AUTOSAR XML (schema 4-2-2)
package /STELLANTIS/EPT/ASWCs
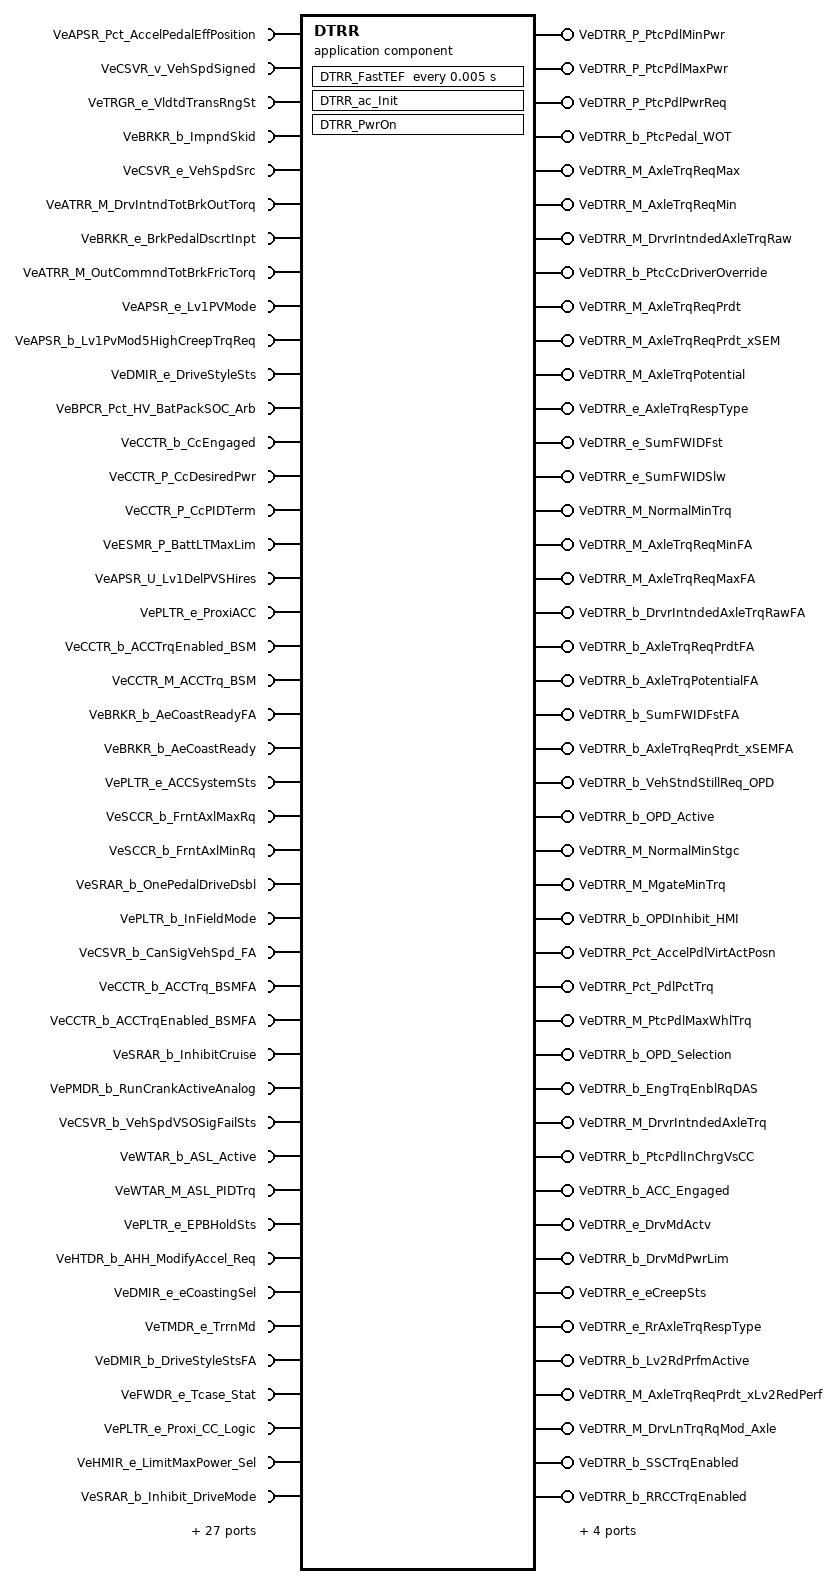
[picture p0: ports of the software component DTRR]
  application sw component type DTRR
    71 x require port:
      VeAPSR_Pct_AccelPedalEffPosition: nonqueued-receiver-com-spec{data-element=Value, init-value=0}, required-interface=VeAPSR_Pct_AccelPedalEffPosition
      VeCSVR_v_VehSpdSigned: nonqueued-receiver-com-spec{data-element=Value, init-value=0}, required-interface=VeCSVR_v_VehSpdSigned
      VeTRGR_e_VldtdTransRngSt: nonqueued-receiver-com-spec{data-element=Value, init-value=CeTRGR_e_NoSelectionAvailable}, required-interface=VeTRGR_e_VldtdTransRngSt
      VeBRKR_b_ImpndSkid: nonqueued-receiver-com-spec{data-element=Value, init-value=0}, required-interface=VeBRKR_b_ImpndSkid
      VeCSVR_e_VehSpdSrc: nonqueued-receiver-com-spec{data-element=Value, init-value=CeCSVR_e_VehSpdFrmCAN}, required-interface=VeCSVR_e_VehSpdSrc
      VeATRR_M_DrvIntndTotBrkOutTorq: nonqueued-receiver-com-spec{data-element=Value, init-value=0}, required-interface=VeATRR_M_DrvIntndTotBrkOutTorq
      VeBRKR_e_BrkPedalDscrtInpt: nonqueued-receiver-com-spec{data-element=Value, init-value=CeBRKR_e_BrkNotApplied}, required-interface=VeBRKR_e_BrkPedalDscrtInpt
      VeATRR_M_OutCommndTotBrkFricTorq: nonqueued-receiver-com-spec{data-element=Value, init-value=0}, required-interface=VeATRR_M_OutCommndTotBrkFricTorq
      VeAPSR_e_Lv1PVMode: nonqueued-receiver-com-spec{data-element=Value, init-value=CeAPSR_e_LV1PVMode_NotValid}, required-interface=VeAPSR_e_Lv1PVMode
      VeAPSR_b_Lv1PvMod5HighCreepTrqReq: nonqueued-receiver-com-spec{data-element=Value, init-value=0}, required-interface=VeAPSR_b_Lv1PvMod5HighCreepTrqReq
      VeDMIR_e_DriveStyleSts: nonqueued-receiver-com-spec{data-element=Value, init-value=CeDMIR_e_Normal}, required-interface=VeDMIR_e_DriveStyleSts
      VeBPCR_Pct_HV_BatPackSOC_Arb: nonqueued-receiver-com-spec{data-element=Value, init-value=0}, required-interface=VeBPCR_Pct_HV_BatPackSOC_Arb
      VeCCTR_b_CcEngaged: nonqueued-receiver-com-spec{data-element=Value, init-value=0}, required-interface=VeCCTR_b_CcEngaged
      VeCCTR_P_CcDesiredPwr: nonqueued-receiver-com-spec{data-element=Value, init-value=0}, required-interface=VeCCTR_P_CcDesiredPwr
      VeCCTR_P_CcPIDTerm: nonqueued-receiver-com-spec{data-element=Value, init-value=0}, required-interface=VeCCTR_P_CcPIDTerm
      VeESMR_P_BattLTMaxLim: nonqueued-receiver-com-spec{data-element=Value, init-value=0}, required-interface=VeESMR_P_BattLTMaxLim
      VeAPSR_U_Lv1DelPVSHires: nonqueued-receiver-com-spec{data-element=Value, init-value=0}, required-interface=VeAPSR_U_Lv1DelPVSHires
      VePLTR_e_ProxiACC: nonqueued-receiver-com-spec{data-element=Value, init-value=CePLTR_e_ACC_Absent}, required-interface=VePLTR_e_ProxiACC
      VeCCTR_b_ACCTrqEnabled_BSM: nonqueued-receiver-com-spec{data-element=Value, init-value=0}, required-interface=VeCCTR_b_ACCTrqEnabled_BSM
      VeCCTR_M_ACCTrq_BSM: nonqueued-receiver-com-spec{data-element=Value, init-value=0}, required-interface=VeCCTR_M_ACCTrq_BSM
      VeBRKR_b_AeCoastReadyFA: nonqueued-receiver-com-spec{data-element=Value, init-value=0}, required-interface=VeBRKR_b_AeCoastReadyFA
      VeBRKR_b_AeCoastReady: nonqueued-receiver-com-spec{data-element=Value, init-value=0}, required-interface=VeBRKR_b_AeCoastReady
      VePLTR_e_ACCSystemSts: nonqueued-receiver-com-spec{data-element=Value, init-value=CePLTR_e_Off}, required-interface=VePLTR_e_ACCSystemSts
      VeSCCR_b_FrntAxlMaxRq: nonqueued-receiver-com-spec{data-element=Value, init-value=0}, required-interface=VeSCCR_b_FrntAxlMaxRq
      VeSCCR_b_FrntAxlMinRq: nonqueued-receiver-com-spec{data-element=Value, init-value=0}, required-interface=VeSCCR_b_FrntAxlMinRq
      VeSRAR_b_OnePedalDriveDsbl: nonqueued-receiver-com-spec{data-element=Value, init-value=0}, required-interface=VeSRAR_b_OnePedalDriveDsbl
      VePLTR_b_InFieldMode: nonqueued-receiver-com-spec{data-element=Value, init-value=0}, required-interface=VePLTR_b_InFieldMode
      VeCSVR_b_CanSigVehSpd_FA: nonqueued-receiver-com-spec{data-element=Value, init-value=0}, required-interface=VeCSVR_b_CanSigVehSpd_FA
      VeCCTR_b_ACCTrq_BSMFA: nonqueued-receiver-com-spec{data-element=Value, init-value=0}, required-interface=VeCCTR_b_ACCTrq_BSMFA
      VeCCTR_b_ACCTrqEnabled_BSMFA: nonqueued-receiver-com-spec{data-element=Value, init-value=0}, required-interface=VeCCTR_b_ACCTrqEnabled_BSMFA
      VeSRAR_b_InhibitCruise: nonqueued-receiver-com-spec{data-element=Value, init-value=0}, required-interface=VeSRAR_b_InhibitCruise
      VePMDR_b_RunCrankActiveAnalog: nonqueued-receiver-com-spec{data-element=Value, init-value=0}, required-interface=VePMDR_b_RunCrankActiveAnalog
      VeCSVR_b_VehSpdVSOSigFailSts: nonqueued-receiver-com-spec{data-element=Value, init-value=0}, required-interface=VeCSVR_b_VehSpdVSOSigFailSts
      VeWTAR_b_ASL_Active: nonqueued-receiver-com-spec{data-element=Value, init-value=0}, required-interface=VeWTAR_b_ASL_Active
      VeWTAR_M_ASL_PIDTrq: nonqueued-receiver-com-spec{data-element=Value, init-value=0}, required-interface=VeWTAR_M_ASL_PIDTrq
      VePLTR_e_EPBHoldSts: nonqueued-receiver-com-spec{data-element=Value, init-value=CePLTR_e_EPBHoldSts_REL}, required-interface=VePLTR_e_EPBHoldSts
      VeHTDR_b_AHH_ModifyAccel_Req: nonqueued-receiver-com-spec{data-element=Value, init-value=0}, required-interface=VeHTDR_b_AHH_ModifyAccel_Req
      VeDMIR_e_eCoastingSel: variation-point={short-label=vpVeDMIR_e_eCoastingSel, sw-syscond=1}, nonqueued-receiver-com-spec{data-element=Value, init-value=CeDMIR_e_Level1}, required-interface=VeDMIR_e_eCoastingSel
      VeTMDR_e_TrrnMd: nonqueued-receiver-com-spec{data-element=Value, init-value=CeTMDR_e_NotDefine}, required-interface=VeTMDR_e_TrrnMd
      VeDMIR_b_DriveStyleStsFA: nonqueued-receiver-com-spec{data-element=Value, init-value=0}, required-interface=VeDMIR_b_DriveStyleStsFA
      VeFWDR_e_Tcase_Stat: nonqueued-receiver-com-spec{data-element=Value, init-value=CeFWDR_e_ShiftINProg}, required-interface=VeFWDR_e_Tcase_Stat
      VePLTR_e_Proxi_CC_Logic: nonqueued-receiver-com-spec{data-element=Value, init-value=CePLTR_e_Logic1}, required-interface=VePLTR_e_Proxi_CC_Logic
      VeHMIR_e_LimitMaxPower_Sel: nonqueued-receiver-com-spec{data-element=Value, init-value=CeHMIR_e_Not_Active}, required-interface=VeHMIR_e_LimitMaxPower_Sel
      VeSRAR_b_Inhibit_DriveMode: nonqueued-receiver-com-spec{data-element=Value, init-value=0}, required-interface=VeSRAR_b_Inhibit_DriveMode
      VeDMDR_e_TurtleMdSts: nonqueued-receiver-com-spec{data-element=Value, init-value=CeDMDR_e_No_Turtle_Mode}, required-interface=VeDMDR_e_TurtleMdSts
      VeBRKR_P_BrkPrss: nonqueued-receiver-com-spec{data-element=Value, init-value=0}, required-interface=VeBRKR_P_BrkPrss
      VePLTR_Pct_EstSlopeAnglePct: nonqueued-receiver-com-spec{data-element=Value, init-value=0}, required-interface=VePLTR_Pct_EstSlopeAnglePct
      VeAPSR_b_Lv1Pv1LimFailed: nonqueued-receiver-com-spec{data-element=Value, init-value=0}, required-interface=VeAPSR_b_Lv1Pv1LimFailed
      VeAPSR_b_Lv1Pv2LimFailed: nonqueued-receiver-com-spec{data-element=Value, init-value=0}, required-interface=VeAPSR_b_Lv1Pv2LimFailed
      VeSCCR_b_RrAxlMaxRq: nonqueued-receiver-com-spec{data-element=Value, init-value=0}, required-interface=VeSCCR_b_RrAxlMaxRq
      VeSCCR_b_RrAxlMinRq: nonqueued-receiver-com-spec{data-element=Value, init-value=0}, required-interface=VeSCCR_b_RrAxlMinRq
      VeCTCR_b_MinCreepWheelTrq_Enable: nonqueued-receiver-com-spec{data-element=Value, init-value=0}, required-interface=VeCTCR_b_MinCreepWheelTrq_Enable
      VeCTCR_M_WheelMin4ECM: nonqueued-receiver-com-spec{data-element=Value, init-value=0}, required-interface=VeCTCR_M_WheelMin4ECM
      VePLTR_b_CC_Type: nonqueued-receiver-com-spec{data-element=Value, init-value=0}, required-interface=VePLTR_b_CC_Type
      VeSTMR_e_RdPrfmMd_MinMax: nonqueued-receiver-com-spec{data-element=Value, init-value=CeSTMR_e_NoRdPerfmMdRq}, required-interface=VeSTMR_e_RdPrfmMd_MinMax
      VeSTMR_M_Lv2ReducedPrfmTrq: nonqueued-receiver-com-spec{data-element=Value, init-value=0}, required-interface=VeSTMR_M_Lv2ReducedPrfmTrq
      VeSTMR_b_Lv2ReducedPerfMode: nonqueued-receiver-com-spec{data-element=Value, init-value=0}, required-interface=VeSTMR_b_Lv2ReducedPerfMode
      VeBTQR_r_TrqDmnConvSumToAxl: nonqueued-receiver-com-spec{data-element=Value, init-value=0}, required-interface=VeBTQR_r_TrqDmnConvSumToAxl
      VeTINR_M_DrvLnTrqRq_Axle: nonqueued-receiver-com-spec{data-element=Value, init-value=0}, required-interface=VeTINR_M_DrvLnTrqRq_Axle
      VeDMIR_e_RegenSts: nonqueued-receiver-com-spec{data-element=Value, init-value=CeDMIR_e_NormalRegen}, required-interface=VeDMIR_e_RegenSts
      VeDMDR_e_DrvMdArb: nonqueued-receiver-com-spec{data-element=Value, init-value=CeDMDR_e_NoDrvMd}, required-interface=VeDMDR_e_DrvMdArb
      VeINVR_e_MtrA_InvrtrSt: nonqueued-receiver-com-spec{data-element=Value, init-value=CeINVR_e_NormalPowerStageOff}, required-interface=VeINVR_e_MtrA_InvrtrSt
      VeINVR_e_MtrB_InvrtrSt: nonqueued-receiver-com-spec{data-element=Value, init-value=CeINVR_e_NormalPowerStageOff}, required-interface=VeINVR_e_MtrB_InvrtrSt
      VePLTR_e_BSM_AxleTrq_Enbld: nonqueued-receiver-com-spec{data-element=Value, init-value=CePLTR_e_No_Req}, required-interface=VePLTR_e_BSM_AxleTrq_Enbld
      VeTMDR_e_PropulsionMd: nonqueued-receiver-com-spec{data-element=Value, init-value=CeTMDR_e_NotDefine}, required-interface=VeTMDR_e_PropulsionMd
      VeDMIR_e_CreepSts: nonqueued-receiver-com-spec{data-element=Value, init-value=CeDMIR_e_CreepOff}, required-interface=VeDMIR_e_CreepSts
      VeAXLR_M_OutTorqReqModHH_Axle: nonqueued-receiver-com-spec{data-element=Value, init-value=0}, required-interface=VeAXLR_M_OutTorqReqModHH_Axle
      VeASLR_e_HDC_Status: nonqueued-receiver-com-spec{data-element=Value, init-value=CeASLR_e_HDC_UNAVL}, required-interface=VeASLR_e_HDC_Status
      VeTMIR_b_RaceDeadPedal: nonqueued-receiver-com-spec{data-element=Value, init-value=0}, required-interface=VeTMIR_b_RaceDeadPedal
      VeEBMR_e_eBoostStatus: nonqueued-receiver-com-spec{data-element=Value, init-value=CeEBMR_e_eBoostOFF}, required-interface=VeEBMR_e_eBoostStatus
      VeGRAR_b_DisableACC: nonqueued-receiver-com-spec{data-element=Value, init-value=0}, required-interface=VeGRAR_b_DisableACC
    48 x provide port:
      VeDTRR_P_PtcPdlMinPwr: nonqueued-sender-com-spec{data-element=Value, init-value=0}, provided-interface=VeDTRR_P_PtcPdlMinPwr
      VeDTRR_P_PtcPdlMaxPwr: nonqueued-sender-com-spec{data-element=Value, init-value=0}, provided-interface=VeDTRR_P_PtcPdlMaxPwr
      VeDTRR_P_PtcPdlPwrReq: nonqueued-sender-com-spec{data-element=Value, init-value=0}, provided-interface=VeDTRR_P_PtcPdlPwrReq
      VeDTRR_b_PtcPedal_WOT: nonqueued-sender-com-spec{data-element=Value, init-value=0}, provided-interface=VeDTRR_b_PtcPedal_WOT
      VeDTRR_M_AxleTrqReqMax: nonqueued-sender-com-spec{data-element=Value, init-value=0}, provided-interface=VeDTRR_M_AxleTrqReqMax
      VeDTRR_M_AxleTrqReqMin: nonqueued-sender-com-spec{data-element=Value, init-value=0}, provided-interface=VeDTRR_M_AxleTrqReqMin
      VeDTRR_M_DrvrIntndedAxleTrqRaw: nonqueued-sender-com-spec{data-element=Value, init-value=0}, provided-interface=VeDTRR_M_DrvrIntndedAxleTrqRaw
      VeDTRR_b_PtcCcDriverOverride: nonqueued-sender-com-spec{data-element=Value, init-value=0}, provided-interface=VeDTRR_b_PtcCcDriverOverride
      VeDTRR_M_AxleTrqReqPrdt: nonqueued-sender-com-spec{data-element=Value, init-value=0}, provided-interface=VeDTRR_M_AxleTrqReqPrdt
      VeDTRR_M_AxleTrqReqPrdt_xSEM: nonqueued-sender-com-spec{data-element=Value, init-value=0}, provided-interface=VeDTRR_M_AxleTrqReqPrdt_xSEM
      VeDTRR_M_AxleTrqPotential: nonqueued-sender-com-spec{data-element=Value, init-value=0}, provided-interface=VeDTRR_M_AxleTrqPotential
      VeDTRR_e_AxleTrqRespType: nonqueued-sender-com-spec{data-element=Value, init-value=CePTAR_e_Inactive}, provided-interface=VeDTRR_e_AxleTrqRespType
      VeDTRR_e_SumFWIDFst: nonqueued-sender-com-spec{data-element=Value, init-value=CeDTRR_e_Potential}, provided-interface=VeDTRR_e_SumFWIDFst
      VeDTRR_e_SumFWIDSlw: nonqueued-sender-com-spec{data-element=Value, init-value=CeDTRR_e_Potential}, provided-interface=VeDTRR_e_SumFWIDSlw
      VeDTRR_M_NormalMinTrq: nonqueued-sender-com-spec{data-element=Value, init-value=0}, provided-interface=VeDTRR_M_NormalMinTrq
      VeDTRR_M_AxleTrqReqMinFA: nonqueued-sender-com-spec{data-element=Value, init-value=0}, provided-interface=VeDTRR_M_AxleTrqReqMinFA
      VeDTRR_M_AxleTrqReqMaxFA: nonqueued-sender-com-spec{data-element=Value, init-value=0}, provided-interface=VeDTRR_M_AxleTrqReqMaxFA
      VeDTRR_b_DrvrIntndedAxleTrqRawFA: nonqueued-sender-com-spec{data-element=Value, init-value=0}, provided-interface=VeDTRR_b_DrvrIntndedAxleTrqRawFA
      VeDTRR_b_AxleTrqReqPrdtFA: nonqueued-sender-com-spec{data-element=Value, init-value=0}, provided-interface=VeDTRR_b_AxleTrqReqPrdtFA
      VeDTRR_b_AxleTrqPotentialFA: nonqueued-sender-com-spec{data-element=Value, init-value=0}, provided-interface=VeDTRR_b_AxleTrqPotentialFA
      VeDTRR_b_SumFWIDFstFA: nonqueued-sender-com-spec{data-element=Value, init-value=0}, provided-interface=VeDTRR_b_SumFWIDFstFA
      VeDTRR_b_AxleTrqReqPrdt_xSEMFA: nonqueued-sender-com-spec{data-element=Value, init-value=0}, provided-interface=VeDTRR_b_AxleTrqReqPrdt_xSEMFA
      VeDTRR_b_VehStndStillReq_OPD: nonqueued-sender-com-spec{data-element=Value, init-value=0}, provided-interface=VeDTRR_b_VehStndStillReq_OPD
      VeDTRR_b_OPD_Active: nonqueued-sender-com-spec{data-element=Value, init-value=0}, provided-interface=VeDTRR_b_OPD_Active
      VeDTRR_M_NormalMinStgc: nonqueued-sender-com-spec{data-element=Value, init-value=0}, provided-interface=VeDTRR_M_NormalMinStgc
      VeDTRR_M_MgateMinTrq: nonqueued-sender-com-spec{data-element=Value, init-value=0}, provided-interface=VeDTRR_M_MgateMinTrq
      VeDTRR_b_OPDInhibit_HMI: nonqueued-sender-com-spec{data-element=Value, init-value=0}, provided-interface=VeDTRR_b_OPDInhibit_HMI
      VeDTRR_Pct_AccelPdlVirtActPosn: nonqueued-sender-com-spec{data-element=Value, init-value=0}, provided-interface=VeDTRR_Pct_AccelPdlVirtActPosn
      VeDTRR_Pct_PdlPctTrq: nonqueued-sender-com-spec{data-element=Value, init-value=0}, provided-interface=VeDTRR_Pct_PdlPctTrq
      VeDTRR_M_PtcPdlMaxWhlTrq: nonqueued-sender-com-spec{data-element=Value, init-value=0}, provided-interface=VeDTRR_M_PtcPdlMaxWhlTrq
      VeDTRR_b_OPD_Selection: nonqueued-sender-com-spec{data-element=Value, init-value=0}, provided-interface=VeDTRR_b_OPD_Selection
      VeDTRR_b_EngTrqEnblRqDAS: nonqueued-sender-com-spec{data-element=Value, init-value=0}, provided-interface=VeDTRR_b_EngTrqEnblRqDAS
      VeDTRR_M_DrvrIntndedAxleTrq: nonqueued-sender-com-spec{data-element=Value, init-value=0}, provided-interface=VeDTRR_M_DrvrIntndedAxleTrq
      VeDTRR_b_PtcPdlInChrgVsCC: nonqueued-sender-com-spec{data-element=Value, init-value=0}, provided-interface=VeDTRR_b_PtcPdlInChrgVsCC
      VeDTRR_b_ACC_Engaged: nonqueued-sender-com-spec{data-element=Value, init-value=0}, provided-interface=VeDTRR_b_ACC_Engaged
      VeDTRR_e_DrvMdActv: nonqueued-sender-com-spec{data-element=Value, init-value=CeDMIR_e_Normal}, provided-interface=VeDTRR_e_DrvMdActv
      VeDTRR_b_DrvMdPwrLim: nonqueued-sender-com-spec{data-element=Value, init-value=0}, provided-interface=VeDTRR_b_DrvMdPwrLim
      VeDTRR_e_eCreepSts: nonqueued-sender-com-spec{data-element=Value, init-value=CeDTRR_e_Off}, provided-interface=VeDTRR_e_eCreepSts
      VeDTRR_e_RrAxleTrqRespType: nonqueued-sender-com-spec{data-element=Value, init-value=CePTAR_e_Inactive}, provided-interface=VeDTRR_e_RrAxleTrqRespType
      VeDTRR_b_Lv2RdPrfmActive: nonqueued-sender-com-spec{data-element=Value, init-value=0}, provided-interface=VeDTRR_b_Lv2RdPrfmActive
      VeDTRR_M_AxleTrqReqPrdt_xLv2RedPerf: nonqueued-sender-com-spec{data-element=Value, init-value=0}, provided-interface=VeDTRR_M_AxleTrqReqPrdt_xLv2RedPerf
      VeDTRR_M_DrvLnTrqRqMod_Axle: nonqueued-sender-com-spec{data-element=Value, init-value=0}, provided-interface=VeDTRR_M_DrvLnTrqRqMod_Axle
      VeDTRR_b_SSCTrqEnabled: nonqueued-sender-com-spec{data-element=Value, init-value=0}, provided-interface=VeDTRR_b_SSCTrqEnabled
      VeDTRR_b_RRCCTrqEnabled: nonqueued-sender-com-spec{data-element=Value, init-value=0}, provided-interface=VeDTRR_b_RRCCTrqEnabled
      VeDTRR_b_ACCTrqEnabled: nonqueued-sender-com-spec{data-element=Value, init-value=0}, provided-interface=VeDTRR_b_ACCTrqEnabled
      VeDTRR_b_PPPATrqEnabled: nonqueued-sender-com-spec{data-element=Value, init-value=0}, provided-interface=VeDTRR_b_PPPATrqEnabled
      VeDTRR_e_OPD_Sts: nonqueued-sender-com-spec{data-element=Value, init-value=CeDTRR_e_Available}, provided-interface=VeDTRR_e_OPD_Sts
      VeDTRR_e_OPD_HMI: nonqueued-sender-com-spec{data-element=Value, init-value=CeDTRR_e_Available}, provided-interface=VeDTRR_e_OPD_HMI
    behavior IB_DTRR: data-type-mapping=msADTtoIDTMapping, handle-termination-and-restart=NO-SUPPORT
      timing event Event_FastTEF: start-on-event=DTRR_FastTEF, period=0.005
      init event Event_DTRR_ac_Init: start-on-event=DTRR_ac_Init
      init event Event_PwrOn: start-on-event=DTRR_PwrOn
      runnable DTRR_ac_Init
        data-send-points:
          8 x access:
            OUT_VeDTRR_e_AxleTrqRespType_Value: accessed-variable=VeDTRR_e_AxleTrqRespType.Value
            OUT_VeDTRR_e_SumFWIDFst_Value: accessed-variable=VeDTRR_e_SumFWIDFst.Value
            OUT_VeDTRR_e_SumFWIDSlw_Value: accessed-variable=VeDTRR_e_SumFWIDSlw.Value
            OUT_VeDTRR_e_DrvMdActv_Value: accessed-variable=VeDTRR_e_DrvMdActv.Value
            OUT_VeDTRR_e_eCreepSts_Value: accessed-variable=VeDTRR_e_eCreepSts.Value
            OUT_VeDTRR_e_RrAxleTrqRespType_Value: accessed-variable=VeDTRR_e_RrAxleTrqRespType.Value
            OUT_VeDTRR_e_OPD_Sts_Value: accessed-variable=VeDTRR_e_OPD_Sts.Value
            OUT_VeDTRR_e_OPD_HMI_Value: accessed-variable=VeDTRR_e_OPD_HMI.Value
      runnable DTRR_FastTEF
        data-receive-point-by-arguments:
          71 x access:
            IN_VeAPSR_Pct_AccelPedalEffPosition_Value: accessed-variable=VeAPSR_Pct_AccelPedalEffPosition.Value
            IN_VeAPSR_U_Lv1DelPVSHires_Value: accessed-variable=VeAPSR_U_Lv1DelPVSHires.Value
            IN_VeAPSR_b_Lv1Pv1LimFailed_Value: accessed-variable=VeAPSR_b_Lv1Pv1LimFailed.Value
            IN_VeAPSR_b_Lv1Pv2LimFailed_Value: accessed-variable=VeAPSR_b_Lv1Pv2LimFailed.Value
            IN_VeAPSR_b_Lv1PvMod5HighCreepTrqReq_Value: accessed-variable=VeAPSR_b_Lv1PvMod5HighCreepTrqReq.Value
            IN_VeAPSR_e_Lv1PVMode_Value: accessed-variable=VeAPSR_e_Lv1PVMode.Value
            IN_VeASLR_e_HDC_Status_Value: accessed-variable=VeASLR_e_HDC_Status.Value
            IN_VeATRR_M_DrvIntndTotBrkOutTorq_Value: accessed-variable=VeATRR_M_DrvIntndTotBrkOutTorq.Value
            IN_VeATRR_M_OutCommndTotBrkFricTorq_Value: accessed-variable=VeATRR_M_OutCommndTotBrkFricTorq.Value
            IN_VeAXLR_M_OutTorqReqModHH_Axle_Value: accessed-variable=VeAXLR_M_OutTorqReqModHH_Axle.Value
            IN_VeBPCR_Pct_HV_BatPackSOC_Arb_Value: accessed-variable=VeBPCR_Pct_HV_BatPackSOC_Arb.Value
            IN_VeBRKR_P_BrkPrss_Value: accessed-variable=VeBRKR_P_BrkPrss.Value
            IN_VeBRKR_b_AeCoastReady_Value: accessed-variable=VeBRKR_b_AeCoastReady.Value
            IN_VeBRKR_b_AeCoastReadyFA_Value: accessed-variable=VeBRKR_b_AeCoastReadyFA.Value
            IN_VeBRKR_b_ImpndSkid_Value: accessed-variable=VeBRKR_b_ImpndSkid.Value
            IN_VeBRKR_e_BrkPedalDscrtInpt_Value: accessed-variable=VeBRKR_e_BrkPedalDscrtInpt.Value
            IN_VeBTQR_r_TrqDmnConvSumToAxl_Value: accessed-variable=VeBTQR_r_TrqDmnConvSumToAxl.Value
            IN_VeCCTR_M_ACCTrq_BSM_Value: accessed-variable=VeCCTR_M_ACCTrq_BSM.Value
            IN_VeCCTR_P_CcDesiredPwr_Value: accessed-variable=VeCCTR_P_CcDesiredPwr.Value
            IN_VeCCTR_P_CcPIDTerm_Value: accessed-variable=VeCCTR_P_CcPIDTerm.Value
            IN_VeCCTR_b_ACCTrqEnabled_BSM_Value: accessed-variable=VeCCTR_b_ACCTrqEnabled_BSM.Value
            IN_VeCCTR_b_ACCTrqEnabled_BSMFA_Value: accessed-variable=VeCCTR_b_ACCTrqEnabled_BSMFA.Value
            IN_VeCCTR_b_ACCTrq_BSMFA_Value: accessed-variable=VeCCTR_b_ACCTrq_BSMFA.Value
            IN_VeCCTR_b_CcEngaged_Value: accessed-variable=VeCCTR_b_CcEngaged.Value
            IN_VeCSVR_b_CanSigVehSpd_FA_Value: accessed-variable=VeCSVR_b_CanSigVehSpd_FA.Value
            IN_VeCSVR_b_VehSpdVSOSigFailSts_Value: accessed-variable=VeCSVR_b_VehSpdVSOSigFailSts.Value
            IN_VeCSVR_e_VehSpdSrc_Value: accessed-variable=VeCSVR_e_VehSpdSrc.Value
            IN_VeCSVR_v_VehSpdSigned_Value: accessed-variable=VeCSVR_v_VehSpdSigned.Value
            IN_VeCTCR_M_WheelMin4ECM_Value: accessed-variable=VeCTCR_M_WheelMin4ECM.Value
            IN_VeCTCR_b_MinCreepWheelTrq_Enable_Value: accessed-variable=VeCTCR_b_MinCreepWheelTrq_Enable.Value
            IN_VeDMDR_e_DrvMdArb_Value: accessed-variable=VeDMDR_e_DrvMdArb.Value
            IN_VeDMDR_e_TurtleMdSts_Value: accessed-variable=VeDMDR_e_TurtleMdSts.Value
            IN_VeDMIR_b_DriveStyleStsFA_Value: accessed-variable=VeDMIR_b_DriveStyleStsFA.Value
            IN_VeDMIR_e_CreepSts_Value: accessed-variable=VeDMIR_e_CreepSts.Value
            IN_VeDMIR_e_DriveStyleSts_Value: accessed-variable=VeDMIR_e_DriveStyleSts.Value
            IN_VeDMIR_e_RegenSts_Value: accessed-variable=VeDMIR_e_RegenSts.Value
            IN_VeDMIR_e_eCoastingSel_Value: accessed-variable=VeDMIR_e_eCoastingSel.Value, variation-point={short-label=vpIN_VeDMIR_e_eCoastingSel_Value, sw-syscond=1}
            IN_VeEBMR_e_eBoostStatus_Value: accessed-variable=VeEBMR_e_eBoostStatus.Value
            IN_VeESMR_P_BattLTMaxLim_Value: accessed-variable=VeESMR_P_BattLTMaxLim.Value
            IN_VeFWDR_e_Tcase_Stat_Value: accessed-variable=VeFWDR_e_Tcase_Stat.Value
            IN_VeGRAR_b_DisableACC_Value: accessed-variable=VeGRAR_b_DisableACC.Value
            IN_VeHMIR_e_LimitMaxPower_Sel_Value: accessed-variable=VeHMIR_e_LimitMaxPower_Sel.Value
            IN_VeHTDR_b_AHH_ModifyAccel_Req_Value: accessed-variable=VeHTDR_b_AHH_ModifyAccel_Req.Value
            IN_VeINVR_e_MtrA_InvrtrSt_Value: accessed-variable=VeINVR_e_MtrA_InvrtrSt.Value
            IN_VeINVR_e_MtrB_InvrtrSt_Value: accessed-variable=VeINVR_e_MtrB_InvrtrSt.Value
            IN_VePLTR_Pct_EstSlopeAnglePct_Value: accessed-variable=VePLTR_Pct_EstSlopeAnglePct.Value
            IN_VePLTR_b_CC_Type_Value: accessed-variable=VePLTR_b_CC_Type.Value
            IN_VePLTR_b_InFieldMode_Value: accessed-variable=VePLTR_b_InFieldMode.Value
            IN_VePLTR_e_ACCSystemSts_Value: accessed-variable=VePLTR_e_ACCSystemSts.Value
            IN_VePLTR_e_BSM_AxleTrq_Enbld_Value: accessed-variable=VePLTR_e_BSM_AxleTrq_Enbld.Value
            IN_VePLTR_e_EPBHoldSts_Value: accessed-variable=VePLTR_e_EPBHoldSts.Value
            IN_VePLTR_e_ProxiACC_Value: accessed-variable=VePLTR_e_ProxiACC.Value
            IN_VePLTR_e_Proxi_CC_Logic_Value: accessed-variable=VePLTR_e_Proxi_CC_Logic.Value
            IN_VePMDR_b_RunCrankActiveAnalog_Value: accessed-variable=VePMDR_b_RunCrankActiveAnalog.Value
            IN_VeSCCR_b_FrntAxlMaxRq_Value: accessed-variable=VeSCCR_b_FrntAxlMaxRq.Value
            IN_VeSCCR_b_FrntAxlMinRq_Value: accessed-variable=VeSCCR_b_FrntAxlMinRq.Value
            IN_VeSCCR_b_RrAxlMaxRq_Value: accessed-variable=VeSCCR_b_RrAxlMaxRq.Value
            IN_VeSCCR_b_RrAxlMinRq_Value: accessed-variable=VeSCCR_b_RrAxlMinRq.Value
            IN_VeSRAR_b_InhibitCruise_Value: accessed-variable=VeSRAR_b_InhibitCruise.Value
            IN_VeSRAR_b_Inhibit_DriveMode_Value: accessed-variable=VeSRAR_b_Inhibit_DriveMode.Value
            IN_VeSRAR_b_OnePedalDriveDsbl_Value: accessed-variable=VeSRAR_b_OnePedalDriveDsbl.Value
            IN_VeSTMR_M_Lv2ReducedPrfmTrq_Value: accessed-variable=VeSTMR_M_Lv2ReducedPrfmTrq.Value
            IN_VeSTMR_b_Lv2ReducedPerfMode_Value: accessed-variable=VeSTMR_b_Lv2ReducedPerfMode.Value
            IN_VeSTMR_e_RdPrfmMd_MinMax_Value: accessed-variable=VeSTMR_e_RdPrfmMd_MinMax.Value
            IN_VeTINR_M_DrvLnTrqRq_Axle_Value: accessed-variable=VeTINR_M_DrvLnTrqRq_Axle.Value
            IN_VeTMDR_e_PropulsionMd_Value: accessed-variable=VeTMDR_e_PropulsionMd.Value
            IN_VeTMDR_e_TrrnMd_Value: accessed-variable=VeTMDR_e_TrrnMd.Value
            IN_VeTMIR_b_RaceDeadPedal_Value: accessed-variable=VeTMIR_b_RaceDeadPedal.Value
            IN_VeTRGR_e_VldtdTransRngSt_Value: accessed-variable=VeTRGR_e_VldtdTransRngSt.Value
            IN_VeWTAR_M_ASL_PIDTrq_Value: accessed-variable=VeWTAR_M_ASL_PIDTrq.Value
            IN_VeWTAR_b_ASL_Active_Value: accessed-variable=VeWTAR_b_ASL_Active.Value
        data-send-points:
          48 x access:
            OUT_VeDTRR_P_PtcPdlMinPwr_Value: accessed-variable=VeDTRR_P_PtcPdlMinPwr.Value
            OUT_VeDTRR_P_PtcPdlMaxPwr_Value: accessed-variable=VeDTRR_P_PtcPdlMaxPwr.Value
            OUT_VeDTRR_P_PtcPdlPwrReq_Value: accessed-variable=VeDTRR_P_PtcPdlPwrReq.Value
            OUT_VeDTRR_b_PtcPedal_WOT_Value: accessed-variable=VeDTRR_b_PtcPedal_WOT.Value
            OUT_VeDTRR_M_AxleTrqReqMax_Value: accessed-variable=VeDTRR_M_AxleTrqReqMax.Value
            OUT_VeDTRR_M_AxleTrqReqMin_Value: accessed-variable=VeDTRR_M_AxleTrqReqMin.Value
            OUT_VeDTRR_M_DrvrIntndedAxleTrqRaw_Value: accessed-variable=VeDTRR_M_DrvrIntndedAxleTrqRaw.Value
            OUT_VeDTRR_b_PtcCcDriverOverride_Value: accessed-variable=VeDTRR_b_PtcCcDriverOverride.Value
            OUT_VeDTRR_M_AxleTrqReqPrdt_Value: accessed-variable=VeDTRR_M_AxleTrqReqPrdt.Value
            OUT_VeDTRR_M_AxleTrqReqPrdt_xSEM_Value: accessed-variable=VeDTRR_M_AxleTrqReqPrdt_xSEM.Value
            OUT_VeDTRR_M_AxleTrqPotential_Value: accessed-variable=VeDTRR_M_AxleTrqPotential.Value
            OUT_VeDTRR_e_AxleTrqRespType_Value: accessed-variable=VeDTRR_e_AxleTrqRespType.Value
            OUT_VeDTRR_e_SumFWIDFst_Value: accessed-variable=VeDTRR_e_SumFWIDFst.Value
            OUT_VeDTRR_e_SumFWIDSlw_Value: accessed-variable=VeDTRR_e_SumFWIDSlw.Value
            OUT_VeDTRR_M_NormalMinTrq_Value: accessed-variable=VeDTRR_M_NormalMinTrq.Value
            OUT_VeDTRR_M_AxleTrqReqMinFA_Value: accessed-variable=VeDTRR_M_AxleTrqReqMinFA.Value
            OUT_VeDTRR_M_AxleTrqReqMaxFA_Value: accessed-variable=VeDTRR_M_AxleTrqReqMaxFA.Value
            OUT_VeDTRR_b_DrvrIntndedAxleTrqRawFA_Value: accessed-variable=VeDTRR_b_DrvrIntndedAxleTrqRawFA.Value
            OUT_VeDTRR_b_AxleTrqReqPrdtFA_Value: accessed-variable=VeDTRR_b_AxleTrqReqPrdtFA.Value
            OUT_VeDTRR_b_AxleTrqPotentialFA_Value: accessed-variable=VeDTRR_b_AxleTrqPotentialFA.Value
            OUT_VeDTRR_b_SumFWIDFstFA_Value: accessed-variable=VeDTRR_b_SumFWIDFstFA.Value
            OUT_VeDTRR_b_AxleTrqReqPrdt_xSEMFA_Value: accessed-variable=VeDTRR_b_AxleTrqReqPrdt_xSEMFA.Value
            OUT_VeDTRR_b_VehStndStillReq_OPD_Value: accessed-variable=VeDTRR_b_VehStndStillReq_OPD.Value
            OUT_VeDTRR_b_OPD_Active_Value: accessed-variable=VeDTRR_b_OPD_Active.Value
            OUT_VeDTRR_M_NormalMinStgc_Value: accessed-variable=VeDTRR_M_NormalMinStgc.Value
            OUT_VeDTRR_M_MgateMinTrq_Value: accessed-variable=VeDTRR_M_MgateMinTrq.Value
            OUT_VeDTRR_b_OPDInhibit_HMI_Value: accessed-variable=VeDTRR_b_OPDInhibit_HMI.Value
            OUT_VeDTRR_Pct_AccelPdlVirtActPosn_Value: accessed-variable=VeDTRR_Pct_AccelPdlVirtActPosn.Value
            OUT_VeDTRR_Pct_PdlPctTrq_Value: accessed-variable=VeDTRR_Pct_PdlPctTrq.Value
            OUT_VeDTRR_M_PtcPdlMaxWhlTrq_Value: accessed-variable=VeDTRR_M_PtcPdlMaxWhlTrq.Value
            OUT_VeDTRR_b_OPD_Selection_Value: accessed-variable=VeDTRR_b_OPD_Selection.Value
            OUT_VeDTRR_b_EngTrqEnblRqDAS_Value: accessed-variable=VeDTRR_b_EngTrqEnblRqDAS.Value
            OUT_VeDTRR_M_DrvrIntndedAxleTrq_Value: accessed-variable=VeDTRR_M_DrvrIntndedAxleTrq.Value
            OUT_VeDTRR_b_PtcPdlInChrgVsCC_Value: accessed-variable=VeDTRR_b_PtcPdlInChrgVsCC.Value
            OUT_VeDTRR_b_ACC_Engaged_Value: accessed-variable=VeDTRR_b_ACC_Engaged.Value
            OUT_VeDTRR_e_DrvMdActv_Value: accessed-variable=VeDTRR_e_DrvMdActv.Value
            OUT_VeDTRR_b_DrvMdPwrLim_Value: accessed-variable=VeDTRR_b_DrvMdPwrLim.Value
            OUT_VeDTRR_e_eCreepSts_Value: accessed-variable=VeDTRR_e_eCreepSts.Value
            OUT_VeDTRR_e_RrAxleTrqRespType_Value: accessed-variable=VeDTRR_e_RrAxleTrqRespType.Value
            OUT_VeDTRR_b_Lv2RdPrfmActive_Value: accessed-variable=VeDTRR_b_Lv2RdPrfmActive.Value
            OUT_VeDTRR_M_AxleTrqReqPrdt_xLv2RedPerf_Value: accessed-variable=VeDTRR_M_AxleTrqReqPrdt_xLv2RedPerf.Value
            OUT_VeDTRR_M_DrvLnTrqRqMod_Axle_Value: accessed-variable=VeDTRR_M_DrvLnTrqRqMod_Axle.Value
            OUT_VeDTRR_b_SSCTrqEnabled_Value: accessed-variable=VeDTRR_b_SSCTrqEnabled.Value
            OUT_VeDTRR_b_RRCCTrqEnabled_Value: accessed-variable=VeDTRR_b_RRCCTrqEnabled.Value
            OUT_VeDTRR_b_ACCTrqEnabled_Value: accessed-variable=VeDTRR_b_ACCTrqEnabled.Value
            OUT_VeDTRR_b_PPPATrqEnabled_Value: accessed-variable=VeDTRR_b_PPPATrqEnabled.Value
            OUT_VeDTRR_e_OPD_Sts_Value: accessed-variable=VeDTRR_e_OPD_Sts.Value
            OUT_VeDTRR_e_OPD_HMI_Value: accessed-variable=VeDTRR_e_OPD_HMI.Value
      runnable DTRR_PwrOn
        data-send-points:
          48 x access:
            OUT_VeDTRR_P_PtcPdlMinPwr_Value: accessed-variable=VeDTRR_P_PtcPdlMinPwr.Value
            OUT_VeDTRR_P_PtcPdlMaxPwr_Value: accessed-variable=VeDTRR_P_PtcPdlMaxPwr.Value
            OUT_VeDTRR_P_PtcPdlPwrReq_Value: accessed-variable=VeDTRR_P_PtcPdlPwrReq.Value
            OUT_VeDTRR_b_PtcPedal_WOT_Value: accessed-variable=VeDTRR_b_PtcPedal_WOT.Value
            OUT_VeDTRR_M_AxleTrqReqMax_Value: accessed-variable=VeDTRR_M_AxleTrqReqMax.Value
            OUT_VeDTRR_M_AxleTrqReqMin_Value: accessed-variable=VeDTRR_M_AxleTrqReqMin.Value
            OUT_VeDTRR_M_DrvrIntndedAxleTrqRaw_Value: accessed-variable=VeDTRR_M_DrvrIntndedAxleTrqRaw.Value
            OUT_VeDTRR_b_PtcCcDriverOverride_Value: accessed-variable=VeDTRR_b_PtcCcDriverOverride.Value
            OUT_VeDTRR_M_AxleTrqReqPrdt_Value: accessed-variable=VeDTRR_M_AxleTrqReqPrdt.Value
            OUT_VeDTRR_M_AxleTrqReqPrdt_xSEM_Value: accessed-variable=VeDTRR_M_AxleTrqReqPrdt_xSEM.Value
            OUT_VeDTRR_M_AxleTrqPotential_Value: accessed-variable=VeDTRR_M_AxleTrqPotential.Value
            OUT_VeDTRR_e_AxleTrqRespType_Value: accessed-variable=VeDTRR_e_AxleTrqRespType.Value
            OUT_VeDTRR_e_SumFWIDFst_Value: accessed-variable=VeDTRR_e_SumFWIDFst.Value
            OUT_VeDTRR_e_SumFWIDSlw_Value: accessed-variable=VeDTRR_e_SumFWIDSlw.Value
            OUT_VeDTRR_M_NormalMinTrq_Value: accessed-variable=VeDTRR_M_NormalMinTrq.Value
            OUT_VeDTRR_M_AxleTrqReqMinFA_Value: accessed-variable=VeDTRR_M_AxleTrqReqMinFA.Value
            OUT_VeDTRR_M_AxleTrqReqMaxFA_Value: accessed-variable=VeDTRR_M_AxleTrqReqMaxFA.Value
            OUT_VeDTRR_b_DrvrIntndedAxleTrqRawFA_Value: accessed-variable=VeDTRR_b_DrvrIntndedAxleTrqRawFA.Value
            OUT_VeDTRR_b_AxleTrqReqPrdtFA_Value: accessed-variable=VeDTRR_b_AxleTrqReqPrdtFA.Value
            OUT_VeDTRR_b_AxleTrqPotentialFA_Value: accessed-variable=VeDTRR_b_AxleTrqPotentialFA.Value
            OUT_VeDTRR_b_SumFWIDFstFA_Value: accessed-variable=VeDTRR_b_SumFWIDFstFA.Value
            OUT_VeDTRR_b_AxleTrqReqPrdt_xSEMFA_Value: accessed-variable=VeDTRR_b_AxleTrqReqPrdt_xSEMFA.Value
            OUT_VeDTRR_b_VehStndStillReq_OPD_Value: accessed-variable=VeDTRR_b_VehStndStillReq_OPD.Value
            OUT_VeDTRR_b_OPD_Active_Value: accessed-variable=VeDTRR_b_OPD_Active.Value
            OUT_VeDTRR_M_NormalMinStgc_Value: accessed-variable=VeDTRR_M_NormalMinStgc.Value
            OUT_VeDTRR_M_MgateMinTrq_Value: accessed-variable=VeDTRR_M_MgateMinTrq.Value
            OUT_VeDTRR_b_OPDInhibit_HMI_Value: accessed-variable=VeDTRR_b_OPDInhibit_HMI.Value
            OUT_VeDTRR_Pct_AccelPdlVirtActPosn_Value: accessed-variable=VeDTRR_Pct_AccelPdlVirtActPosn.Value
            OUT_VeDTRR_Pct_PdlPctTrq_Value: accessed-variable=VeDTRR_Pct_PdlPctTrq.Value
            OUT_VeDTRR_M_PtcPdlMaxWhlTrq_Value: accessed-variable=VeDTRR_M_PtcPdlMaxWhlTrq.Value
            OUT_VeDTRR_b_OPD_Selection_Value: accessed-variable=VeDTRR_b_OPD_Selection.Value
            OUT_VeDTRR_b_EngTrqEnblRqDAS_Value: accessed-variable=VeDTRR_b_EngTrqEnblRqDAS.Value
            OUT_VeDTRR_M_DrvrIntndedAxleTrq_Value: accessed-variable=VeDTRR_M_DrvrIntndedAxleTrq.Value
            OUT_VeDTRR_b_PtcPdlInChrgVsCC_Value: accessed-variable=VeDTRR_b_PtcPdlInChrgVsCC.Value
            OUT_VeDTRR_b_ACC_Engaged_Value: accessed-variable=VeDTRR_b_ACC_Engaged.Value
            OUT_VeDTRR_e_DrvMdActv_Value: accessed-variable=VeDTRR_e_DrvMdActv.Value
            OUT_VeDTRR_b_DrvMdPwrLim_Value: accessed-variable=VeDTRR_b_DrvMdPwrLim.Value
            OUT_VeDTRR_e_eCreepSts_Value: accessed-variable=VeDTRR_e_eCreepSts.Value
            OUT_VeDTRR_e_RrAxleTrqRespType_Value: accessed-variable=VeDTRR_e_RrAxleTrqRespType.Value
            OUT_VeDTRR_b_Lv2RdPrfmActive_Value: accessed-variable=VeDTRR_b_Lv2RdPrfmActive.Value
            OUT_VeDTRR_M_AxleTrqReqPrdt_xLv2RedPerf_Value: accessed-variable=VeDTRR_M_AxleTrqReqPrdt_xLv2RedPerf.Value
            OUT_VeDTRR_M_DrvLnTrqRqMod_Axle_Value: accessed-variable=VeDTRR_M_DrvLnTrqRqMod_Axle.Value
            OUT_VeDTRR_b_SSCTrqEnabled_Value: accessed-variable=VeDTRR_b_SSCTrqEnabled.Value
            OUT_VeDTRR_b_RRCCTrqEnabled_Value: accessed-variable=VeDTRR_b_RRCCTrqEnabled.Value
            OUT_VeDTRR_b_ACCTrqEnabled_Value: accessed-variable=VeDTRR_b_ACCTrqEnabled.Value
            OUT_VeDTRR_b_PPPATrqEnabled_Value: accessed-variable=VeDTRR_b_PPPATrqEnabled.Value
            OUT_VeDTRR_e_OPD_Sts_Value: accessed-variable=VeDTRR_e_OPD_Sts.Value
            OUT_VeDTRR_e_OPD_HMI_Value: accessed-variable=VeDTRR_e_OPD_HMI.Value
      5 x variation point proxy, all with category=CONDITION:
        Variant_DTRR_FUNC_1: condition-access=1
        Variant_DTRR_FUNC_2: condition-access=0
        Variant_DTRR_FUNC_3: condition-access=0
        Variant_DTRR_FUNC_4: condition-access=1
        Variant_DTRR_FUNC_5: condition-access=0
